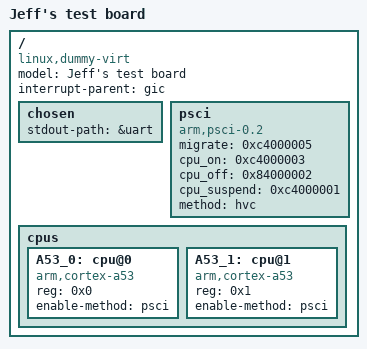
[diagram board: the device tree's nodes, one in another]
/*
 * ARM Ltd. Juno Platform
 *
 * Copyright (c) 2013-2014 ARM Ltd.
 *
 * This file is licensed under a dual GPLv2 or BSD license.
 */

/dts-v1/;
#include <dt-bindings/interrupt-controller/arm-gic.h>
#include "test-board-base-minimal.dtsi"

/ {
	model = "Jeff's test board";
	compatible = "linux,dummy-virt";
	interrupt-parent = <&gic>;
	#address-cells = <2>;
	#size-cells = <2>;

	chosen {
		stdout-path = &uart;
	};

	psci {
		migrate = <0xc4000005>;
		cpu_on = <0xc4000003>;
		cpu_off = <0x84000002>;
		cpu_suspend = <0xc4000001>;
		method = "hvc";
		compatible = "arm,psci-0.2\0arm,psci";
	};

	cpus {
		#address-cells = <1>;
		#size-cells = <0>;

		A53_0: cpu@0 {
			compatible = "arm,cortex-a53";
			reg = <0x0>;
			device_type = "cpu";
			enable-method = "psci";
		};

		A53_1: cpu@1 {
			compatible = "arm,cortex-a53";
			reg = <0x1>;
			device_type = "cpu";
			enable-method = "psci";
		};
	};
};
